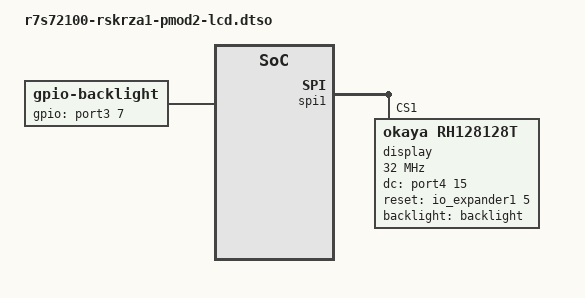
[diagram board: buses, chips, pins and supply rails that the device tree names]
// SPDX-License-Identifier: GPL-2.0-only
//
// Device Tree Overlay for Okaya LCD on RSK+RZA1 PMOD Connector 2 (CN26)
//
// Copyright (C) 2019 Glider bvba

/dts-v1/;
/plugin/;

#include <dt-bindings/gpio/gpio.h>

&{/} {
	backlight: backlight {
		compatible = "gpio-backlight";
		gpios = <&port3 7 GPIO_ACTIVE_HIGH>;
	};
};

&spi1 {
	#address-cells = <1>;
	#size-cells = <0>;

	display@1 {
		compatible = "okaya,rh128128t", "sitronix,st7715r";
		reg = <1>;

		spi-max-frequency = <32000000>;
		dc-gpios = <&port4 15 GPIO_ACTIVE_HIGH>;
		reset-gpios = <&io_expander1 5 GPIO_ACTIVE_HIGH>;
		backlight = &backlight;
	};
};
